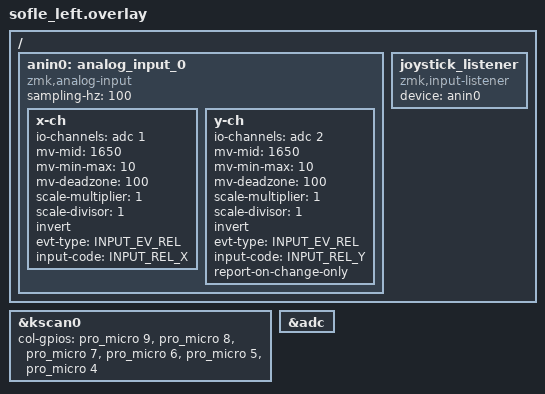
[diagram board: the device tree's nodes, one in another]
/*
 * Copyright (c) 2020 Ryan Cross
 *
 * SPDX-License-Identifier: MIT
 */

#include "sofle.dtsi"

&kscan0 {
    	col-gpios
        	= <&pro_micro 9 GPIO_ACTIVE_HIGH>
        	, <&pro_micro 8 GPIO_ACTIVE_HIGH>
        	, <&pro_micro 7 GPIO_ACTIVE_HIGH>
        	, <&pro_micro 6 GPIO_ACTIVE_HIGH>
        	, <&pro_micro 5 GPIO_ACTIVE_HIGH>
        	, <&pro_micro 4 GPIO_ACTIVE_HIGH>
        	;
};



&adc {
	status = "okay";
};

/ {
	anin0: analog_input_0 {
		compatible = "zmk,analog-input";
		sampling-hz = <100>;
		x-ch {
			io-channels = <&adc 1>;
			mv-mid = <1650>;
			mv-min-max = <10>;
			mv-deadzone = <100>;
			scale-multiplier = <1>;
			scale-divisor = <1>;
			invert;
			evt-type = <INPUT_EV_REL>;
			input-code = <INPUT_REL_X>;
		};
		y-ch {
			io-channels = <&adc 2>;
			mv-mid = <1650>;
			mv-min-max = <10>;
			mv-deadzone = <100>;
			scale-multiplier = <1>;
			scale-divisor = <1>;
			invert;
			evt-type = <INPUT_EV_REL>;
			input-code = <INPUT_REL_Y>;

			/* enable report mdoe for gamepad axix or knob */
			/* to only call input_report on quantquantized value is updated */
			report-on-change-only;

		};
	};

    joystick_listener {
        compatible = "zmk,input-listener";
        device = <&anin0>;
    };
};
